# VPAC0_COMMON_0_IVPAC_TOP_0_CFG_SLV_PAR_VPAC_VISS0_S_VBUSP_VISS_FCP_FCC_VBUSP_FLEXCC_LINE register map
Vendor: Texas Instruments
Peripheral module from a debugger description file (folder am62A).
Registers are 32-bit, read-write, reset 0x0 unless marked. A register's access mark holds for its fields unless they carry their own. Offsets are as the file gives them; lines under a group give offsets from that group; [hi:lo] are bit positions; {n}, {i} and the like mark numbered series; 'fields as' and 'values as' point back to an identical list; <NAME> marks a mode.

## VPAC0_COMMON_0_IVPAC_TOP_0_CFG_SLV_PAR_VPAC_VISS0_S_VBUSP_VISS_FCP_FCC_VBUSP_FLEXCC_LINE
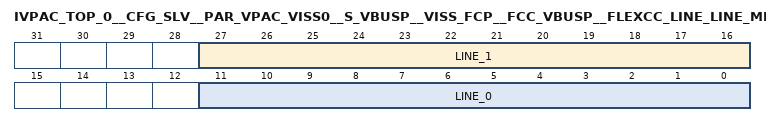
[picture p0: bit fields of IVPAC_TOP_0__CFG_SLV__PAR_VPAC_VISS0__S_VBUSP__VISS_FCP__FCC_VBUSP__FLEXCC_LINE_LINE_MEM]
0x00 IVPAC_TOP_0__CFG_SLV__PAR_VPAC_VISS0__S_VBUSP__VISS_FCP__FCC_VBUSP__FLEXCC_LINE_LINE_MEM — Memory for 2 lines of yuv444to420
  [27:16] LINE_1, [11:0] LINE_0
